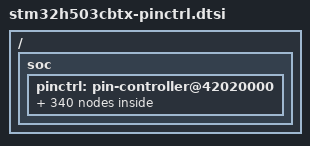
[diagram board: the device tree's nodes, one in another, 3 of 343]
/*
 * NOTE: Autogenerated file using genpinctrl.py
 *
 * SPDX-License-Identifier: Apache-2.0
 */

#include <zephyr/dt-bindings/pinctrl/stm32-pinctrl.h>

/ {
	soc {
		pinctrl: pin-controller@42020000 {

			/* ADC_IN / ADC_INN / ADC_INP */

			/omit-if-no-ref/ adc1_inn1_pa0: adc1_inn1_pa0 {
				pinmux = <STM32_PINMUX('A', 0, ANALOG)>;
			};

			/omit-if-no-ref/ adc1_inp0_pa0: adc1_inp0_pa0 {
				pinmux = <STM32_PINMUX('A', 0, ANALOG)>;
			};

			/omit-if-no-ref/ adc1_inp1_pa1: adc1_inp1_pa1 {
				pinmux = <STM32_PINMUX('A', 1, ANALOG)>;
			};

			/omit-if-no-ref/ adc1_inp14_pa2: adc1_inp14_pa2 {
				pinmux = <STM32_PINMUX('A', 2, ANALOG)>;
			};

			/omit-if-no-ref/ adc1_inp15_pa3: adc1_inp15_pa3 {
				pinmux = <STM32_PINMUX('A', 3, ANALOG)>;
			};

			/omit-if-no-ref/ adc1_inp18_pa4: adc1_inp18_pa4 {
				pinmux = <STM32_PINMUX('A', 4, ANALOG)>;
			};

			/omit-if-no-ref/ adc1_inn18_pa5: adc1_inn18_pa5 {
				pinmux = <STM32_PINMUX('A', 5, ANALOG)>;
			};

			/omit-if-no-ref/ adc1_inp19_pa5: adc1_inp19_pa5 {
				pinmux = <STM32_PINMUX('A', 5, ANALOG)>;
			};

			/omit-if-no-ref/ adc1_inp3_pa6: adc1_inp3_pa6 {
				pinmux = <STM32_PINMUX('A', 6, ANALOG)>;
			};

			/omit-if-no-ref/ adc1_inn3_pa7: adc1_inn3_pa7 {
				pinmux = <STM32_PINMUX('A', 7, ANALOG)>;
			};

			/omit-if-no-ref/ adc1_inp7_pa7: adc1_inp7_pa7 {
				pinmux = <STM32_PINMUX('A', 7, ANALOG)>;
			};

			/omit-if-no-ref/ adc1_inn5_pb0: adc1_inn5_pb0 {
				pinmux = <STM32_PINMUX('B', 0, ANALOG)>;
			};

			/omit-if-no-ref/ adc1_inp9_pb0: adc1_inp9_pb0 {
				pinmux = <STM32_PINMUX('B', 0, ANALOG)>;
			};

			/omit-if-no-ref/ adc1_inp5_pb1: adc1_inp5_pb1 {
				pinmux = <STM32_PINMUX('B', 1, ANALOG)>;
			};

			/* Analog */

			/omit-if-no-ref/ analog_pa0: analog_pa0 {
				pinmux = <STM32_PINMUX('A', 0, ANALOG)>;
			};

			/omit-if-no-ref/ analog_pa1: analog_pa1 {
				pinmux = <STM32_PINMUX('A', 1, ANALOG)>;
			};

			/omit-if-no-ref/ analog_pa2: analog_pa2 {
				pinmux = <STM32_PINMUX('A', 2, ANALOG)>;
			};

			/omit-if-no-ref/ analog_pa3: analog_pa3 {
				pinmux = <STM32_PINMUX('A', 3, ANALOG)>;
			};

			/omit-if-no-ref/ analog_pa4: analog_pa4 {
				pinmux = <STM32_PINMUX('A', 4, ANALOG)>;
			};

			/omit-if-no-ref/ analog_pa5: analog_pa5 {
				pinmux = <STM32_PINMUX('A', 5, ANALOG)>;
			};

			/omit-if-no-ref/ analog_pa6: analog_pa6 {
				pinmux = <STM32_PINMUX('A', 6, ANALOG)>;
			};

			/omit-if-no-ref/ analog_pa7: analog_pa7 {
				pinmux = <STM32_PINMUX('A', 7, ANALOG)>;
			};

			/omit-if-no-ref/ analog_pa8: analog_pa8 {
				pinmux = <STM32_PINMUX('A', 8, ANALOG)>;
			};

			/omit-if-no-ref/ analog_pa9: analog_pa9 {
				pinmux = <STM32_PINMUX('A', 9, ANALOG)>;
			};

			/omit-if-no-ref/ analog_pa10: analog_pa10 {
				pinmux = <STM32_PINMUX('A', 10, ANALOG)>;
			};

			/omit-if-no-ref/ analog_pa11: analog_pa11 {
				pinmux = <STM32_PINMUX('A', 11, ANALOG)>;
			};

			/omit-if-no-ref/ analog_pa12: analog_pa12 {
				pinmux = <STM32_PINMUX('A', 12, ANALOG)>;
			};

			/omit-if-no-ref/ analog_pa13: analog_pa13 {
				pinmux = <STM32_PINMUX('A', 13, ANALOG)>;
			};

			/omit-if-no-ref/ analog_pa14: analog_pa14 {
				pinmux = <STM32_PINMUX('A', 14, ANALOG)>;
			};

			/omit-if-no-ref/ analog_pa15: analog_pa15 {
				pinmux = <STM32_PINMUX('A', 15, ANALOG)>;
			};

			/omit-if-no-ref/ analog_pb0: analog_pb0 {
				pinmux = <STM32_PINMUX('B', 0, ANALOG)>;
			};

			/omit-if-no-ref/ analog_pb1: analog_pb1 {
				pinmux = <STM32_PINMUX('B', 1, ANALOG)>;
			};

			/omit-if-no-ref/ analog_pb2: analog_pb2 {
				pinmux = <STM32_PINMUX('B', 2, ANALOG)>;
			};

			/omit-if-no-ref/ analog_pb3: analog_pb3 {
				pinmux = <STM32_PINMUX('B', 3, ANALOG)>;
			};

			/omit-if-no-ref/ analog_pb4: analog_pb4 {
				pinmux = <STM32_PINMUX('B', 4, ANALOG)>;
			};

			/omit-if-no-ref/ analog_pb5: analog_pb5 {
				pinmux = <STM32_PINMUX('B', 5, ANALOG)>;
			};

			/omit-if-no-ref/ analog_pb6: analog_pb6 {
				pinmux = <STM32_PINMUX('B', 6, ANALOG)>;
			};

			/omit-if-no-ref/ analog_pb7: analog_pb7 {
				pinmux = <STM32_PINMUX('B', 7, ANALOG)>;
			};

			/omit-if-no-ref/ analog_pb8: analog_pb8 {
				pinmux = <STM32_PINMUX('B', 8, ANALOG)>;
			};

			/omit-if-no-ref/ analog_pb10: analog_pb10 {
				pinmux = <STM32_PINMUX('B', 10, ANALOG)>;
			};

			/omit-if-no-ref/ analog_pb12: analog_pb12 {
				pinmux = <STM32_PINMUX('B', 12, ANALOG)>;
			};

			/omit-if-no-ref/ analog_pb13: analog_pb13 {
				pinmux = <STM32_PINMUX('B', 13, ANALOG)>;
			};

			/omit-if-no-ref/ analog_pb14: analog_pb14 {
				pinmux = <STM32_PINMUX('B', 14, ANALOG)>;
			};

			/omit-if-no-ref/ analog_pb15: analog_pb15 {
				pinmux = <STM32_PINMUX('B', 15, ANALOG)>;
			};

			/omit-if-no-ref/ analog_pc13: analog_pc13 {
				pinmux = <STM32_PINMUX('C', 13, ANALOG)>;
			};

			/omit-if-no-ref/ analog_pc14: analog_pc14 {
				pinmux = <STM32_PINMUX('C', 14, ANALOG)>;
			};

			/omit-if-no-ref/ analog_pc15: analog_pc15 {
				pinmux = <STM32_PINMUX('C', 15, ANALOG)>;
			};

			/omit-if-no-ref/ analog_ph0: analog_ph0 {
				pinmux = <STM32_PINMUX('H', 0, ANALOG)>;
			};

			/omit-if-no-ref/ analog_ph1: analog_ph1 {
				pinmux = <STM32_PINMUX('H', 1, ANALOG)>;
			};

			/* COMP_IN */

			/omit-if-no-ref/ comp1_inp_pa0: comp1_inp_pa0 {
				pinmux = <STM32_PINMUX('A', 0, ANALOG)>;
			};

			/omit-if-no-ref/ comp1_inm_pa5: comp1_inm_pa5 {
				pinmux = <STM32_PINMUX('A', 5, ANALOG)>;
			};

			/omit-if-no-ref/ comp1_inp_pb0: comp1_inp_pb0 {
				pinmux = <STM32_PINMUX('B', 0, ANALOG)>;
			};

			/omit-if-no-ref/ comp1_inm_pb1: comp1_inm_pb1 {
				pinmux = <STM32_PINMUX('B', 1, ANALOG)>;
			};

			/omit-if-no-ref/ comp1_inp_pb2: comp1_inp_pb2 {
				pinmux = <STM32_PINMUX('B', 2, ANALOG)>;
			};

			/* COMP_OUT */

			/omit-if-no-ref/ comp1_out_pa13: comp1_out_pa13 {
				pinmux = <STM32_PINMUX('A', 13, AF12)>;
			};

			/omit-if-no-ref/ comp1_out_pb1: comp1_out_pb1 {
				pinmux = <STM32_PINMUX('B', 1, AF12)>;
			};

			/omit-if-no-ref/ comp1_out_pb15: comp1_out_pb15 {
				pinmux = <STM32_PINMUX('B', 15, AF12)>;
			};

			/* DAC_OUT */

			/omit-if-no-ref/ dac1_out1_pa4: dac1_out1_pa4 {
				pinmux = <STM32_PINMUX('A', 4, ANALOG)>;
			};

			/omit-if-no-ref/ dac1_out2_pa5: dac1_out2_pa5 {
				pinmux = <STM32_PINMUX('A', 5, ANALOG)>;
			};

			/* FDCAN_RX */

			/omit-if-no-ref/ fdcan1_rx_pa8: fdcan1_rx_pa8 {
				pinmux = <STM32_PINMUX('A', 8, AF9)>;
			};

			/omit-if-no-ref/ fdcan1_rx_pa11: fdcan1_rx_pa11 {
				pinmux = <STM32_PINMUX('A', 11, AF9)>;
			};

			/omit-if-no-ref/ fdcan1_rx_pb3: fdcan1_rx_pb3 {
				pinmux = <STM32_PINMUX('B', 3, AF9)>;
			};

			/omit-if-no-ref/ fdcan1_rx_pb5: fdcan1_rx_pb5 {
				pinmux = <STM32_PINMUX('B', 5, AF9)>;
			};

			/omit-if-no-ref/ fdcan1_rx_pb8: fdcan1_rx_pb8 {
				pinmux = <STM32_PINMUX('B', 8, AF9)>;
			};

			/omit-if-no-ref/ fdcan1_rx_pb12: fdcan1_rx_pb12 {
				pinmux = <STM32_PINMUX('B', 12, AF9)>;
			};

			/* FDCAN_TX */

			/omit-if-no-ref/ fdcan1_tx_pa12: fdcan1_tx_pa12 {
				pinmux = <STM32_PINMUX('A', 12, AF9)>;
			};

			/omit-if-no-ref/ fdcan1_tx_pb4: fdcan1_tx_pb4 {
				pinmux = <STM32_PINMUX('B', 4, AF9)>;
			};

			/omit-if-no-ref/ fdcan1_tx_pb6: fdcan1_tx_pb6 {
				pinmux = <STM32_PINMUX('B', 6, AF9)>;
			};

			/omit-if-no-ref/ fdcan1_tx_pb7: fdcan1_tx_pb7 {
				pinmux = <STM32_PINMUX('B', 7, AF9)>;
			};

			/omit-if-no-ref/ fdcan1_tx_pb10: fdcan1_tx_pb10 {
				pinmux = <STM32_PINMUX('B', 10, AF9)>;
			};

			/omit-if-no-ref/ fdcan1_tx_pb13: fdcan1_tx_pb13 {
				pinmux = <STM32_PINMUX('B', 13, AF9)>;
			};

			/omit-if-no-ref/ fdcan1_tx_pb15: fdcan1_tx_pb15 {
				pinmux = <STM32_PINMUX('B', 15, AF9)>;
			};

			/* I2C_SCL */

			/omit-if-no-ref/ i2c1_scl_pb6: i2c1_scl_pb6 {
				pinmux = <STM32_PINMUX('B', 6, AF4)>;
				bias-pull-up;
				drive-open-drain;
			};

			/omit-if-no-ref/ i2c1_scl_pb8: i2c1_scl_pb8 {
				pinmux = <STM32_PINMUX('B', 8, AF4)>;
				bias-pull-up;
				drive-open-drain;
			};

			/omit-if-no-ref/ i2c2_scl_pb3: i2c2_scl_pb3 {
				pinmux = <STM32_PINMUX('B', 3, AF8)>;
				bias-pull-up;
				drive-open-drain;
			};

			/omit-if-no-ref/ i2c2_scl_pb5: i2c2_scl_pb5 {
				pinmux = <STM32_PINMUX('B', 5, AF8)>;
				bias-pull-up;
				drive-open-drain;
			};

			/omit-if-no-ref/ i2c2_scl_pb10: i2c2_scl_pb10 {
				pinmux = <STM32_PINMUX('B', 10, AF4)>;
				bias-pull-up;
				drive-open-drain;
			};

			/* I2C_SDA */

			/omit-if-no-ref/ i2c1_sda_pb5: i2c1_sda_pb5 {
				pinmux = <STM32_PINMUX('B', 5, AF11)>;
				bias-pull-up;
				drive-open-drain;
			};

			/omit-if-no-ref/ i2c1_sda_pb7: i2c1_sda_pb7 {
				pinmux = <STM32_PINMUX('B', 7, AF4)>;
				bias-pull-up;
				drive-open-drain;
			};

			/omit-if-no-ref/ i2c1_sda_pb10: i2c1_sda_pb10 {
				pinmux = <STM32_PINMUX('B', 10, AF11)>;
				bias-pull-up;
				drive-open-drain;
			};

			/omit-if-no-ref/ i2c2_sda_pb3: i2c2_sda_pb3 {
				pinmux = <STM32_PINMUX('B', 3, AF4)>;
				bias-pull-up;
				drive-open-drain;
			};

			/omit-if-no-ref/ i2c2_sda_pb4: i2c2_sda_pb4 {
				pinmux = <STM32_PINMUX('B', 4, AF8)>;
				bias-pull-up;
				drive-open-drain;
			};

			/omit-if-no-ref/ i2c2_sda_pb8: i2c2_sda_pb8 {
				pinmux = <STM32_PINMUX('B', 8, AF8)>;
				bias-pull-up;
				drive-open-drain;
			};

			/omit-if-no-ref/ i2c2_sda_pb13: i2c2_sda_pb13 {
				pinmux = <STM32_PINMUX('B', 13, AF4)>;
				bias-pull-up;
				drive-open-drain;
			};

			/* I2C_SMBA */

			/omit-if-no-ref/ i2c1_smba_pb3: i2c1_smba_pb3 {
				pinmux = <STM32_PINMUX('B', 3, AF11)>;
				bias-pull-up;
			};

			/omit-if-no-ref/ i2c1_smba_pb4: i2c1_smba_pb4 {
				pinmux = <STM32_PINMUX('B', 4, AF11)>;
				bias-pull-up;
			};

			/omit-if-no-ref/ i2c1_smba_pb5: i2c1_smba_pb5 {
				pinmux = <STM32_PINMUX('B', 5, AF4)>;
				bias-pull-up;
			};

			/omit-if-no-ref/ i2c1_smba_pb13: i2c1_smba_pb13 {
				pinmux = <STM32_PINMUX('B', 13, AF11)>;
				bias-pull-up;
			};

			/omit-if-no-ref/ i2c2_smba_pb7: i2c2_smba_pb7 {
				pinmux = <STM32_PINMUX('B', 7, AF11)>;
				bias-pull-up;
			};

			/omit-if-no-ref/ i2c2_smba_pb8: i2c2_smba_pb8 {
				pinmux = <STM32_PINMUX('B', 8, AF11)>;
				bias-pull-up;
			};

			/omit-if-no-ref/ i2c2_smba_pb12: i2c2_smba_pb12 {
				pinmux = <STM32_PINMUX('B', 12, AF4)>;
				bias-pull-up;
			};

			/* I2S_CK */

			/omit-if-no-ref/ i2s1_ck_pa2: i2s1_ck_pa2 {
				pinmux = <STM32_PINMUX('A', 2, AF4)>;
				slew-rate = "very-high-speed";
			};

			/omit-if-no-ref/ i2s1_ck_pa5: i2s1_ck_pa5 {
				pinmux = <STM32_PINMUX('A', 5, AF5)>;
				slew-rate = "very-high-speed";
			};

			/omit-if-no-ref/ i2s1_ck_pa8: i2s1_ck_pa8 {
				pinmux = <STM32_PINMUX('A', 8, AF12)>;
				slew-rate = "very-high-speed";
			};

			/omit-if-no-ref/ i2s1_ck_pb3: i2s1_ck_pb3 {
				pinmux = <STM32_PINMUX('B', 3, AF5)>;
				slew-rate = "very-high-speed";
			};

			/omit-if-no-ref/ i2s2_ck_pa5: i2s2_ck_pa5 {
				pinmux = <STM32_PINMUX('A', 5, AF7)>;
				slew-rate = "very-high-speed";
			};

			/omit-if-no-ref/ i2s2_ck_pa9: i2s2_ck_pa9 {
				pinmux = <STM32_PINMUX('A', 9, AF5)>;
				slew-rate = "very-high-speed";
			};

			/omit-if-no-ref/ i2s2_ck_pa12: i2s2_ck_pa12 {
				pinmux = <STM32_PINMUX('A', 12, AF5)>;
				slew-rate = "very-high-speed";
			};

			/omit-if-no-ref/ i2s2_ck_pb2: i2s2_ck_pb2 {
				pinmux = <STM32_PINMUX('B', 2, AF6)>;
				slew-rate = "very-high-speed";
			};

			/omit-if-no-ref/ i2s2_ck_pb10: i2s2_ck_pb10 {
				pinmux = <STM32_PINMUX('B', 10, AF5)>;
				slew-rate = "very-high-speed";
			};

			/omit-if-no-ref/ i2s2_ck_pb13: i2s2_ck_pb13 {
				pinmux = <STM32_PINMUX('B', 13, AF5)>;
				slew-rate = "very-high-speed";
			};

			/omit-if-no-ref/ i2s3_ck_pa1: i2s3_ck_pa1 {
				pinmux = <STM32_PINMUX('A', 1, AF6)>;
				slew-rate = "very-high-speed";
			};

			/omit-if-no-ref/ i2s3_ck_pa15: i2s3_ck_pa15 {
				pinmux = <STM32_PINMUX('A', 15, AF10)>;
				slew-rate = "very-high-speed";
			};

			/omit-if-no-ref/ i2s3_ck_pb3: i2s3_ck_pb3 {
				pinmux = <STM32_PINMUX('B', 3, AF6)>;
				slew-rate = "very-high-speed";
			};

			/omit-if-no-ref/ i2s3_ck_pb7: i2s3_ck_pb7 {
				pinmux = <STM32_PINMUX('B', 7, AF6)>;
				slew-rate = "very-high-speed";
			};

			/* I2S_MCK */

			/omit-if-no-ref/ i2s1_mck_pa5: i2s1_mck_pa5 {
				pinmux = <STM32_PINMUX('A', 5, AF6)>;
				slew-rate = "very-high-speed";
			};

			/omit-if-no-ref/ i2s1_mck_pa7: i2s1_mck_pa7 {
				pinmux = <STM32_PINMUX('A', 7, AF4)>;
				slew-rate = "very-high-speed";
			};

			/omit-if-no-ref/ i2s1_mck_pb6: i2s1_mck_pb6 {
				pinmux = <STM32_PINMUX('B', 6, AF5)>;
				slew-rate = "very-high-speed";
			};

			/omit-if-no-ref/ i2s2_mck_pa0: i2s2_mck_pa0 {
				pinmux = <STM32_PINMUX('A', 0, AF11)>;
				slew-rate = "very-high-speed";
			};

			/omit-if-no-ref/ i2s2_mck_pa7: i2s2_mck_pa7 {
				pinmux = <STM32_PINMUX('A', 7, AF6)>;
				slew-rate = "very-high-speed";
			};

			/omit-if-no-ref/ i2s2_mck_pb3: i2s2_mck_pb3 {
				pinmux = <STM32_PINMUX('B', 3, AF7)>;
				slew-rate = "very-high-speed";
			};

			/omit-if-no-ref/ i2s2_mck_pb8: i2s2_mck_pb8 {
				pinmux = <STM32_PINMUX('B', 8, AF6)>;
				slew-rate = "very-high-speed";
			};

			/omit-if-no-ref/ i2s3_mck_pa7: i2s3_mck_pa7 {
				pinmux = <STM32_PINMUX('A', 7, AF10)>;
				slew-rate = "very-high-speed";
			};

			/omit-if-no-ref/ i2s3_mck_pb7: i2s3_mck_pb7 {
				pinmux = <STM32_PINMUX('B', 7, AF10)>;
				slew-rate = "very-high-speed";
			};

			/omit-if-no-ref/ i2s3_mck_pb15: i2s3_mck_pb15 {
				pinmux = <STM32_PINMUX('B', 15, AF10)>;
				slew-rate = "very-high-speed";
			};

			/* I2S_WS */

			/omit-if-no-ref/ i2s1_ws_pa1: i2s1_ws_pa1 {
				pinmux = <STM32_PINMUX('A', 1, AF4)>;
			};

			/omit-if-no-ref/ i2s1_ws_pa4: i2s1_ws_pa4 {
				pinmux = <STM32_PINMUX('A', 4, AF5)>;
			};

			/omit-if-no-ref/ i2s1_ws_pa15: i2s1_ws_pa15 {
				pinmux = <STM32_PINMUX('A', 15, AF5)>;
			};

			/omit-if-no-ref/ i2s1_ws_pb8: i2s1_ws_pb8 {
				pinmux = <STM32_PINMUX('B', 8, AF12)>;
			};

			/omit-if-no-ref/ i2s2_ws_pa3: i2s2_ws_pa3 {
				pinmux = <STM32_PINMUX('A', 3, AF5)>;
			};

			/omit-if-no-ref/ i2s2_ws_pa8: i2s2_ws_pa8 {
				pinmux = <STM32_PINMUX('A', 8, AF11)>;
			};

			/omit-if-no-ref/ i2s2_ws_pa11: i2s2_ws_pa11 {
				pinmux = <STM32_PINMUX('A', 11, AF5)>;
			};

			/omit-if-no-ref/ i2s2_ws_pb4: i2s2_ws_pb4 {
				pinmux = <STM32_PINMUX('B', 4, AF7)>;
			};

			/omit-if-no-ref/ i2s2_ws_pb12: i2s2_ws_pb12 {
				pinmux = <STM32_PINMUX('B', 12, AF5)>;
			};

			/omit-if-no-ref/ i2s3_ws_pa0: i2s3_ws_pa0 {
				pinmux = <STM32_PINMUX('A', 0, AF10)>;
			};

			/omit-if-no-ref/ i2s3_ws_pa4: i2s3_ws_pa4 {
				pinmux = <STM32_PINMUX('A', 4, AF6)>;
			};

			/omit-if-no-ref/ i2s3_ws_pa15: i2s3_ws_pa15 {
				pinmux = <STM32_PINMUX('A', 15, AF6)>;
			};

			/omit-if-no-ref/ i2s3_ws_pb10: i2s3_ws_pb10 {
				pinmux = <STM32_PINMUX('B', 10, AF6)>;
			};

			/* I3C_SCL */

			/omit-if-no-ref/ i3c1_scl_pb6: i3c1_scl_pb6 {
				pinmux = <STM32_PINMUX('B', 6, AF3)>;
				slew-rate = "very-high-speed";
			};

			/omit-if-no-ref/ i3c1_scl_pb8: i3c1_scl_pb8 {
				pinmux = <STM32_PINMUX('B', 8, AF3)>;
				slew-rate = "very-high-speed";
			};

			/omit-if-no-ref/ i3c2_scl_pb3: i3c2_scl_pb3 {
				pinmux = <STM32_PINMUX('B', 3, AF3)>;
				slew-rate = "very-high-speed";
			};

			/omit-if-no-ref/ i3c2_scl_pb5: i3c2_scl_pb5 {
				pinmux = <STM32_PINMUX('B', 5, AF3)>;
				slew-rate = "very-high-speed";
			};

			/omit-if-no-ref/ i3c2_scl_pb10: i3c2_scl_pb10 {
				pinmux = <STM32_PINMUX('B', 10, AF10)>;
				slew-rate = "very-high-speed";
			};

			/* I3C_SDA */

			/omit-if-no-ref/ i3c1_sda_pb5: i3c1_sda_pb5 {
				pinmux = <STM32_PINMUX('B', 5, AF10)>;
				slew-rate = "very-high-speed";
			};

			/omit-if-no-ref/ i3c1_sda_pb7: i3c1_sda_pb7 {
				pinmux = <STM32_PINMUX('B', 7, AF3)>;
				slew-rate = "very-high-speed";
			};

			/omit-if-no-ref/ i3c1_sda_pb10: i3c1_sda_pb10 {
				pinmux = <STM32_PINMUX('B', 10, AF8)>;
				slew-rate = "very-high-speed";
			};

			/omit-if-no-ref/ i3c2_sda_pb4: i3c2_sda_pb4 {
				pinmux = <STM32_PINMUX('B', 4, AF3)>;
				slew-rate = "very-high-speed";
			};

			/omit-if-no-ref/ i3c2_sda_pb8: i3c2_sda_pb8 {
				pinmux = <STM32_PINMUX('B', 8, AF10)>;
				slew-rate = "very-high-speed";
			};

			/omit-if-no-ref/ i3c2_sda_pb13: i3c2_sda_pb13 {
				pinmux = <STM32_PINMUX('B', 13, AF10)>;
				slew-rate = "very-high-speed";
			};

			/* JTAG PORT */

			/omit-if-no-ref/ debug_jtms_swdio_pa13: debug_jtms_swdio_pa13 {
				pinmux = <STM32_PINMUX('A', 13, AF0)>;
			};

			/omit-if-no-ref/ debug_jtck_swclk_pa14: debug_jtck_swclk_pa14 {
				pinmux = <STM32_PINMUX('A', 14, AF0)>;
			};

			/omit-if-no-ref/ debug_jtdi_pa15: debug_jtdi_pa15 {
				pinmux = <STM32_PINMUX('A', 15, AF0)>;
			};

			/omit-if-no-ref/ debug_jtdo_swo_pb3: debug_jtdo_swo_pb3 {
				pinmux = <STM32_PINMUX('B', 3, AF0)>;
			};

			/omit-if-no-ref/ debug_jtrst_pb4: debug_jtrst_pb4 {
				pinmux = <STM32_PINMUX('B', 4, AF0)>;
			};

			/* OPAMP */

			/omit-if-no-ref/ opamp1_vinp_pa0: opamp1_vinp_pa0 {
				pinmux = <STM32_PINMUX('A', 0, ANALOG)>;
			};

			/omit-if-no-ref/ opamp1_vout_pa7: opamp1_vout_pa7 {
				pinmux = <STM32_PINMUX('A', 7, ANALOG)>;
			};

			/omit-if-no-ref/ opamp1_vinp_pb0: opamp1_vinp_pb0 {
				pinmux = <STM32_PINMUX('B', 0, ANALOG)>;
			};

			/omit-if-no-ref/ opamp1_vinm_pb1: opamp1_vinm_pb1 {
				pinmux = <STM32_PINMUX('B', 1, ANALOG)>;
			};

			/* RCC_MCO */

			/omit-if-no-ref/ rcc_mco_1_pa8: rcc_mco_1_pa8 {
				pinmux = <STM32_PINMUX('A', 8, AF0)>;
				slew-rate = "very-high-speed";
			};

			/* SPI_MISO */

			/omit-if-no-ref/ spi1_miso_pa0: spi1_miso_pa0 {
				pinmux = <STM32_PINMUX('A', 0, AF12)>;
				bias-pull-down;
			};

			/omit-if-no-ref/ spi1_miso_pa3: spi1_miso_pa3 {
				pinmux = <STM32_PINMUX('A', 3, AF4)>;
				bias-pull-down;
			};

			/omit-if-no-ref/ spi1_miso_pa6: spi1_miso_pa6 {
				pinmux = <STM32_PINMUX('A', 6, AF5)>;
				bias-pull-down;
			};

			/omit-if-no-ref/ spi1_miso_pa9: spi1_miso_pa9 {
				pinmux = <STM32_PINMUX('A', 9, AF4)>;
				bias-pull-down;
			};

			/omit-if-no-ref/ spi1_miso_pb4: spi1_miso_pb4 {
				pinmux = <STM32_PINMUX('B', 4, AF5)>;
				bias-pull-down;
			};

			/omit-if-no-ref/ spi2_miso_pa7: spi2_miso_pa7 {
				pinmux = <STM32_PINMUX('A', 7, AF11)>;
				bias-pull-down;
			};

			/omit-if-no-ref/ spi2_miso_pa15: spi2_miso_pa15 {
				pinmux = <STM32_PINMUX('A', 15, AF7)>;
				bias-pull-down;
			};

			/omit-if-no-ref/ spi2_miso_pb5: spi2_miso_pb5 {
				pinmux = <STM32_PINMUX('B', 5, AF6)>;
				bias-pull-down;
			};

			/omit-if-no-ref/ spi2_miso_pb14: spi2_miso_pb14 {
				pinmux = <STM32_PINMUX('B', 14, AF5)>;
				bias-pull-down;
			};

			/omit-if-no-ref/ spi3_miso_pa2: spi3_miso_pa2 {
				pinmux = <STM32_PINMUX('A', 2, AF6)>;
				bias-pull-down;
			};

			/omit-if-no-ref/ spi3_miso_pa4: spi3_miso_pa4 {
				pinmux = <STM32_PINMUX('A', 4, AF10)>;
				bias-pull-down;
			};

			/omit-if-no-ref/ spi3_miso_pb4: spi3_miso_pb4 {
				pinmux = <STM32_PINMUX('B', 4, AF6)>;
				bias-pull-down;
			};

			/omit-if-no-ref/ spi3_miso_pb15: spi3_miso_pb15 {
				pinmux = <STM32_PINMUX('B', 15, AF6)>;
				bias-pull-down;
			};

			/* SPI_MOSI */

			/omit-if-no-ref/ spi1_mosi_pa4: spi1_mosi_pa4 {
				pinmux = <STM32_PINMUX('A', 4, AF4)>;
				bias-pull-down;
			};

			/omit-if-no-ref/ spi1_mosi_pa7: spi1_mosi_pa7 {
				pinmux = <STM32_PINMUX('A', 7, AF5)>;
				bias-pull-down;
			};

			/omit-if-no-ref/ spi1_mosi_pb5: spi1_mosi_pb5 {
				pinmux = <STM32_PINMUX('B', 5, AF5)>;
				bias-pull-down;
			};

			/omit-if-no-ref/ spi2_mosi_pa8: spi2_mosi_pa8 {
				pinmux = <STM32_PINMUX('A', 8, AF6)>;
				bias-pull-down;
			};

			/omit-if-no-ref/ spi2_mosi_pb1: spi2_mosi_pb1 {
				pinmux = <STM32_PINMUX('B', 1, AF6)>;
				bias-pull-down;
			};

			/omit-if-no-ref/ spi2_mosi_pb15: spi2_mosi_pb15 {
				pinmux = <STM32_PINMUX('B', 15, AF5)>;
				bias-pull-down;
			};

			/omit-if-no-ref/ spi3_mosi_pa3: spi3_mosi_pa3 {
				pinmux = <STM32_PINMUX('A', 3, AF6)>;
				bias-pull-down;
			};

			/omit-if-no-ref/ spi3_mosi_pa5: spi3_mosi_pa5 {
				pinmux = <STM32_PINMUX('A', 5, AF10)>;
				bias-pull-down;
			};

			/omit-if-no-ref/ spi3_mosi_pa9: spi3_mosi_pa9 {
				pinmux = <STM32_PINMUX('A', 9, AF10)>;
				bias-pull-down;
			};

			/omit-if-no-ref/ spi3_mosi_pb2: spi3_mosi_pb2 {
				pinmux = <STM32_PINMUX('B', 2, AF7)>;
				bias-pull-down;
			};

			/omit-if-no-ref/ spi3_mosi_pb5: spi3_mosi_pb5 {
				pinmux = <STM32_PINMUX('B', 5, AF7)>;
				bias-pull-down;
			};

			/* SPI_NSS */

			/omit-if-no-ref/ spi1_nss_pa1: spi1_nss_pa1 {
				pinmux = <STM32_PINMUX('A', 1, AF4)>;
				bias-pull-up;
			};

			/omit-if-no-ref/ spi1_nss_pa4: spi1_nss_pa4 {
				pinmux = <STM32_PINMUX('A', 4, AF5)>;
				bias-pull-up;
			};

			/omit-if-no-ref/ spi1_nss_pa15: spi1_nss_pa15 {
				pinmux = <STM32_PINMUX('A', 15, AF5)>;
				bias-pull-up;
			};

			/omit-if-no-ref/ spi1_nss_pb8: spi1_nss_pb8 {
				pinmux = <STM32_PINMUX('B', 8, AF12)>;
				bias-pull-up;
			};

			/omit-if-no-ref/ spi2_nss_pa3: spi2_nss_pa3 {
				pinmux = <STM32_PINMUX('A', 3, AF5)>;
				bias-pull-up;
			};

			/omit-if-no-ref/ spi2_nss_pa8: spi2_nss_pa8 {
				pinmux = <STM32_PINMUX('A', 8, AF11)>;
				bias-pull-up;
			};

			/omit-if-no-ref/ spi2_nss_pa11: spi2_nss_pa11 {
				pinmux = <STM32_PINMUX('A', 11, AF5)>;
				bias-pull-up;
			};

			/omit-if-no-ref/ spi2_nss_pb4: spi2_nss_pb4 {
				pinmux = <STM32_PINMUX('B', 4, AF7)>;
				bias-pull-up;
			};

			/omit-if-no-ref/ spi2_nss_pb12: spi2_nss_pb12 {
				pinmux = <STM32_PINMUX('B', 12, AF5)>;
				bias-pull-up;
			};

			/omit-if-no-ref/ spi3_nss_pa0: spi3_nss_pa0 {
				pinmux = <STM32_PINMUX('A', 0, AF10)>;
				bias-pull-up;
			};

			/omit-if-no-ref/ spi3_nss_pa4: spi3_nss_pa4 {
				pinmux = <STM32_PINMUX('A', 4, AF6)>;
				bias-pull-up;
			};

			/omit-if-no-ref/ spi3_nss_pa15: spi3_nss_pa15 {
				pinmux = <STM32_PINMUX('A', 15, AF6)>;
				bias-pull-up;
			};

			/omit-if-no-ref/ spi3_nss_pb10: spi3_nss_pb10 {
				pinmux = <STM32_PINMUX('B', 10, AF6)>;
				bias-pull-up;
			};

			/* SPI_SCK */

			/omit-if-no-ref/ spi1_sck_pa2: spi1_sck_pa2 {
				pinmux = <STM32_PINMUX('A', 2, AF4)>;
				bias-pull-down;
				slew-rate = "very-high-speed";
			};

			/omit-if-no-ref/ spi1_sck_pa5: spi1_sck_pa5 {
				pinmux = <STM32_PINMUX('A', 5, AF5)>;
				bias-pull-down;
				slew-rate = "very-high-speed";
			};

			/omit-if-no-ref/ spi1_sck_pa8: spi1_sck_pa8 {
				pinmux = <STM32_PINMUX('A', 8, AF12)>;
				bias-pull-down;
				slew-rate = "very-high-speed";
			};

			/omit-if-no-ref/ spi1_sck_pb3: spi1_sck_pb3 {
				pinmux = <STM32_PINMUX('B', 3, AF5)>;
				bias-pull-down;
				slew-rate = "very-high-speed";
			};

			/omit-if-no-ref/ spi2_sck_pa5: spi2_sck_pa5 {
				pinmux = <STM32_PINMUX('A', 5, AF7)>;
				bias-pull-down;
				slew-rate = "very-high-speed";
			};

			/omit-if-no-ref/ spi2_sck_pa9: spi2_sck_pa9 {
				pinmux = <STM32_PINMUX('A', 9, AF5)>;
				bias-pull-down;
				slew-rate = "very-high-speed";
			};

			/omit-if-no-ref/ spi2_sck_pa12: spi2_sck_pa12 {
				pinmux = <STM32_PINMUX('A', 12, AF5)>;
				bias-pull-down;
				slew-rate = "very-high-speed";
			};

			/omit-if-no-ref/ spi2_sck_pb2: spi2_sck_pb2 {
				pinmux = <STM32_PINMUX('B', 2, AF6)>;
				bias-pull-down;
				slew-rate = "very-high-speed";
			};

			/omit-if-no-ref/ spi2_sck_pb10: spi2_sck_pb10 {
				pinmux = <STM32_PINMUX('B', 10, AF5)>;
				bias-pull-down;
				slew-rate = "very-high-speed";
			};

			/omit-if-no-ref/ spi2_sck_pb13: spi2_sck_pb13 {
				pinmux = <STM32_PINMUX('B', 13, AF5)>;
				bias-pull-down;
				slew-rate = "very-high-speed";
			};

			/omit-if-no-ref/ spi3_sck_pa1: spi3_sck_pa1 {
				pinmux = <STM32_PINMUX('A', 1, AF6)>;
				bias-pull-down;
				slew-rate = "very-high-speed";
			};

			/omit-if-no-ref/ spi3_sck_pa15: spi3_sck_pa15 {
				pinmux = <STM32_PINMUX('A', 15, AF10)>;
				bias-pull-down;
				slew-rate = "very-high-speed";
			};

			/omit-if-no-ref/ spi3_sck_pb3: spi3_sck_pb3 {
				pinmux = <STM32_PINMUX('B', 3, AF6)>;
				bias-pull-down;
				slew-rate = "very-high-speed";
			};

			/omit-if-no-ref/ spi3_sck_pb7: spi3_sck_pb7 {
				pinmux = <STM32_PINMUX('B', 7, AF6)>;
				bias-pull-down;
				slew-rate = "very-high-speed";
			};

			/* TIM_BKIN */

			/omit-if-no-ref/ tim1_bkin_pa4: tim1_bkin_pa4 {
				pinmux = <STM32_PINMUX('A', 4, AF14)>;
			};

			/omit-if-no-ref/ tim1_bkin_pa6: tim1_bkin_pa6 {
				pinmux = <STM32_PINMUX('A', 6, AF1)>;
			};

			/omit-if-no-ref/ tim1_bkin_pb3: tim1_bkin_pb3 {
				pinmux = <STM32_PINMUX('B', 3, AF14)>;
			};

			/omit-if-no-ref/ tim1_bkin2_pb8: tim1_bkin2_pb8 {
				pinmux = <STM32_PINMUX('B', 8, AF1)>;
			};

			/omit-if-no-ref/ tim1_bkin_pb12: tim1_bkin_pb12 {
				pinmux = <STM32_PINMUX('B', 12, AF1)>;
			};

			/* TIM_CH / TIM_CHN */

			/omit-if-no-ref/ tim1_ch3_pa1: tim1_ch3_pa1 {
				pinmux = <STM32_PINMUX('A', 1, AF14)>;
			};

			/omit-if-no-ref/ tim1_ch4_pa2: tim1_ch4_pa2 {
				pinmux = <STM32_PINMUX('A', 2, AF14)>;
			};

			/omit-if-no-ref/ tim1_ch1n_pa3: tim1_ch1n_pa3 {
				pinmux = <STM32_PINMUX('A', 3, AF14)>;
			};

			/omit-if-no-ref/ tim1_ch2n_pa4: tim1_ch2n_pa4 {
				pinmux = <STM32_PINMUX('A', 4, AF1)>;
			};

			/omit-if-no-ref/ tim1_ch1n_pa7: tim1_ch1n_pa7 {
				pinmux = <STM32_PINMUX('A', 7, AF1)>;
			};

			/omit-if-no-ref/ tim1_ch1_pa8: tim1_ch1_pa8 {
				pinmux = <STM32_PINMUX('A', 8, AF1)>;
			};

			/omit-if-no-ref/ tim1_ch4n_pa8: tim1_ch4n_pa8 {
				pinmux = <STM32_PINMUX('A', 8, AF14)>;
			};

			/omit-if-no-ref/ tim1_ch2_pa9: tim1_ch2_pa9 {
				pinmux = <STM32_PINMUX('A', 9, AF1)>;
			};

			/omit-if-no-ref/ tim1_ch3_pa10: tim1_ch3_pa10 {
				pinmux = <STM32_PINMUX('A', 10, AF1)>;
			};

			/omit-if-no-ref/ tim1_ch4_pa11: tim1_ch4_pa11 {
				pinmux = <STM32_PINMUX('A', 11, AF1)>;
			};

			/omit-if-no-ref/ tim1_ch1_pa13: tim1_ch1_pa13 {
				pinmux = <STM32_PINMUX('A', 13, AF1)>;
			};

			/omit-if-no-ref/ tim1_ch2_pa14: tim1_ch2_pa14 {
				pinmux = <STM32_PINMUX('A', 14, AF1)>;
			};

			/omit-if-no-ref/ tim1_ch4n_pa14: tim1_ch4n_pa14 {
				pinmux = <STM32_PINMUX('A', 14, AF14)>;
			};

			/omit-if-no-ref/ tim1_ch2n_pb0: tim1_ch2n_pb0 {
				pinmux = <STM32_PINMUX('B', 0, AF1)>;
			};

			/omit-if-no-ref/ tim1_ch1_pb1: tim1_ch1_pb1 {
				pinmux = <STM32_PINMUX('B', 1, AF14)>;
			};

			/omit-if-no-ref/ tim1_ch3n_pb1: tim1_ch3n_pb1 {
				pinmux = <STM32_PINMUX('B', 1, AF1)>;
			};

			/omit-if-no-ref/ tim1_ch2n_pb2: tim1_ch2n_pb2 {
				pinmux = <STM32_PINMUX('B', 2, AF1)>;
			};

			/omit-if-no-ref/ tim1_ch2_pb4: tim1_ch2_pb4 {
				pinmux = <STM32_PINMUX('B', 4, AF14)>;
			};

			/omit-if-no-ref/ tim1_ch4n_pb4: tim1_ch4n_pb4 {
				pinmux = <STM32_PINMUX('B', 4, AF1)>;
			};

			/omit-if-no-ref/ tim1_ch3_pb5: tim1_ch3_pb5 {
				pinmux = <STM32_PINMUX('B', 5, AF1)>;
			};

			/omit-if-no-ref/ tim1_ch2_pb6: tim1_ch2_pb6 {
				pinmux = <STM32_PINMUX('B', 6, AF14)>;
			};

			/omit-if-no-ref/ tim1_ch3n_pb6: tim1_ch3n_pb6 {
				pinmux = <STM32_PINMUX('B', 6, AF1)>;
			};

			/omit-if-no-ref/ tim1_ch1_pb7: tim1_ch1_pb7 {
				pinmux = <STM32_PINMUX('B', 7, AF14)>;
			};

			/omit-if-no-ref/ tim1_ch2n_pb7: tim1_ch2n_pb7 {
				pinmux = <STM32_PINMUX('B', 7, AF1)>;
			};

			/omit-if-no-ref/ tim1_ch1n_pb13: tim1_ch1n_pb13 {
				pinmux = <STM32_PINMUX('B', 13, AF1)>;
			};

			/omit-if-no-ref/ tim1_ch2n_pb14: tim1_ch2n_pb14 {
				pinmux = <STM32_PINMUX('B', 14, AF1)>;
			};

			/omit-if-no-ref/ tim1_ch3n_pb15: tim1_ch3n_pb15 {
				pinmux = <STM32_PINMUX('B', 15, AF1)>;
			};

			/omit-if-no-ref/ tim2_ch1_pa0: tim2_ch1_pa0 {
				pinmux = <STM32_PINMUX('A', 0, AF1)>;
			};

			/omit-if-no-ref/ tim2_ch2_pa1: tim2_ch2_pa1 {
				pinmux = <STM32_PINMUX('A', 1, AF1)>;
			};

			/omit-if-no-ref/ tim2_ch3_pa2: tim2_ch3_pa2 {
				pinmux = <STM32_PINMUX('A', 2, AF1)>;
			};

			/omit-if-no-ref/ tim2_ch4_pa3: tim2_ch4_pa3 {
				pinmux = <STM32_PINMUX('A', 3, AF1)>;
			};

			/omit-if-no-ref/ tim2_ch1_pa5: tim2_ch1_pa5 {
				pinmux = <STM32_PINMUX('A', 5, AF1)>;
			};

			/omit-if-no-ref/ tim2_ch3_pa7: tim2_ch3_pa7 {
				pinmux = <STM32_PINMUX('A', 7, AF14)>;
			};

			/omit-if-no-ref/ tim2_ch4_pa12: tim2_ch4_pa12 {
				pinmux = <STM32_PINMUX('A', 12, AF14)>;
			};

			/omit-if-no-ref/ tim2_ch1_pa15: tim2_ch1_pa15 {
				pinmux = <STM32_PINMUX('A', 15, AF1)>;
			};

			/omit-if-no-ref/ tim2_ch1_pb2: tim2_ch1_pb2 {
				pinmux = <STM32_PINMUX('B', 2, AF14)>;
			};

			/omit-if-no-ref/ tim2_ch2_pb3: tim2_ch2_pb3 {
				pinmux = <STM32_PINMUX('B', 3, AF1)>;
			};

			/omit-if-no-ref/ tim2_ch3_pb10: tim2_ch3_pb10 {
				pinmux = <STM32_PINMUX('B', 10, AF1)>;
			};

			/omit-if-no-ref/ tim3_ch1_pa0: tim3_ch1_pa0 {
				pinmux = <STM32_PINMUX('A', 0, AF2)>;
			};

			/omit-if-no-ref/ tim3_ch1_pa6: tim3_ch1_pa6 {
				pinmux = <STM32_PINMUX('A', 6, AF2)>;
			};

			/omit-if-no-ref/ tim3_ch2_pa7: tim3_ch2_pa7 {
				pinmux = <STM32_PINMUX('A', 7, AF2)>;
			};

			/omit-if-no-ref/ tim3_ch3_pa8: tim3_ch3_pa8 {
				pinmux = <STM32_PINMUX('A', 8, AF2)>;
			};

			/omit-if-no-ref/ tim3_ch2_pa11: tim3_ch2_pa11 {
				pinmux = <STM32_PINMUX('A', 11, AF2)>;
			};

			/omit-if-no-ref/ tim3_ch4_pa12: tim3_ch4_pa12 {
				pinmux = <STM32_PINMUX('A', 12, AF2)>;
			};

			/omit-if-no-ref/ tim3_ch1_pa14: tim3_ch1_pa14 {
				pinmux = <STM32_PINMUX('A', 14, AF2)>;
			};

			/omit-if-no-ref/ tim3_ch3_pb0: tim3_ch3_pb0 {
				pinmux = <STM32_PINMUX('B', 0, AF2)>;
			};

			/omit-if-no-ref/ tim3_ch4_pb1: tim3_ch4_pb1 {
				pinmux = <STM32_PINMUX('B', 1, AF2)>;
			};

			/omit-if-no-ref/ tim3_ch1_pb4: tim3_ch1_pb4 {
				pinmux = <STM32_PINMUX('B', 4, AF2)>;
			};

			/omit-if-no-ref/ tim3_ch2_pb5: tim3_ch2_pb5 {
				pinmux = <STM32_PINMUX('B', 5, AF2)>;
			};

			/omit-if-no-ref/ tim3_ch3_pb6: tim3_ch3_pb6 {
				pinmux = <STM32_PINMUX('B', 6, AF2)>;
			};

			/omit-if-no-ref/ tim3_ch4_pb15: tim3_ch4_pb15 {
				pinmux = <STM32_PINMUX('B', 15, AF14)>;
			};

			/* UART_CTS / USART_CTS / LPUART_CTS */

			/omit-if-no-ref/ usart1_cts_pa0: usart1_cts_pa0 {
				pinmux = <STM32_PINMUX('A', 0, AF8)>;
				bias-pull-up;
			};

			/omit-if-no-ref/ lpuart1_cts_pa8: lpuart1_cts_pa8 {
				pinmux = <STM32_PINMUX('A', 8, AF8)>;
				bias-pull-up;
			};

			/omit-if-no-ref/ lpuart1_cts_pa11: lpuart1_cts_pa11 {
				pinmux = <STM32_PINMUX('A', 11, AF3)>;
				bias-pull-up;
			};

			/omit-if-no-ref/ usart1_cts_pa11: usart1_cts_pa11 {
				pinmux = <STM32_PINMUX('A', 11, AF7)>;
				bias-pull-up;
			};

			/omit-if-no-ref/ lpuart1_cts_pa13: lpuart1_cts_pa13 {
				pinmux = <STM32_PINMUX('A', 13, AF8)>;
				bias-pull-up;
			};

			/omit-if-no-ref/ usart1_cts_pa15: usart1_cts_pa15 {
				pinmux = <STM32_PINMUX('A', 15, AF8)>;
				bias-pull-up;
			};

			/omit-if-no-ref/ lpuart1_cts_pb13: lpuart1_cts_pb13 {
				pinmux = <STM32_PINMUX('B', 13, AF8)>;
				bias-pull-up;
			};

			/omit-if-no-ref/ usart2_cts_pa0: usart2_cts_pa0 {
				pinmux = <STM32_PINMUX('A', 0, AF7)>;
				bias-pull-up;
			};

			/omit-if-no-ref/ usart2_cts_pa5: usart2_cts_pa5 {
				pinmux = <STM32_PINMUX('A', 5, AF11)>;
				bias-pull-up;
			};

			/omit-if-no-ref/ usart2_cts_pb6: usart2_cts_pb6 {
				pinmux = <STM32_PINMUX('B', 6, AF11)>;
				bias-pull-up;
			};

			/omit-if-no-ref/ usart3_cts_pa0: usart3_cts_pa0 {
				pinmux = <STM32_PINMUX('A', 0, AF9)>;
				bias-pull-up;
			};

			/omit-if-no-ref/ usart3_cts_pb13: usart3_cts_pb13 {
				pinmux = <STM32_PINMUX('B', 13, AF7)>;
				bias-pull-up;
			};

			/omit-if-no-ref/ usart3_cts_pb15: usart3_cts_pb15 {
				pinmux = <STM32_PINMUX('B', 15, AF7)>;
				bias-pull-up;
			};

			/* UART_DE / USART_DE / LPUART_DE */

			/omit-if-no-ref/ usart1_de_pa4: usart1_de_pa4 {
				pinmux = <STM32_PINMUX('A', 4, AF8)>;
				drive-push-pull;
			};

			/omit-if-no-ref/ lpuart1_de_pa5: lpuart1_de_pa5 {
				pinmux = <STM32_PINMUX('A', 5, AF8)>;
				drive-push-pull;
			};

			/omit-if-no-ref/ usart1_de_pa7: usart1_de_pa7 {
				pinmux = <STM32_PINMUX('A', 7, AF8)>;
				drive-push-pull;
			};

			/omit-if-no-ref/ lpuart1_de_pa12: lpuart1_de_pa12 {
				pinmux = <STM32_PINMUX('A', 12, AF3)>;
				drive-push-pull;
			};

			/omit-if-no-ref/ usart1_de_pa12: usart1_de_pa12 {
				pinmux = <STM32_PINMUX('A', 12, AF7)>;
				drive-push-pull;
			};

			/omit-if-no-ref/ lpuart1_de_pa14: lpuart1_de_pa14 {
				pinmux = <STM32_PINMUX('A', 14, AF8)>;
				drive-push-pull;
			};

			/omit-if-no-ref/ lpuart1_de_pb14: lpuart1_de_pb14 {
				pinmux = <STM32_PINMUX('B', 14, AF8)>;
				drive-push-pull;
			};

			/omit-if-no-ref/ usart2_de_pa1: usart2_de_pa1 {
				pinmux = <STM32_PINMUX('A', 1, AF7)>;
				drive-push-pull;
			};

			/omit-if-no-ref/ usart2_de_pa15: usart2_de_pa15 {
				pinmux = <STM32_PINMUX('A', 15, AF11)>;
				drive-push-pull;
			};

			/omit-if-no-ref/ usart2_de_pb15: usart2_de_pb15 {
				pinmux = <STM32_PINMUX('B', 15, AF11)>;
				drive-push-pull;
			};

			/omit-if-no-ref/ usart3_de_pa7: usart3_de_pa7 {
				pinmux = <STM32_PINMUX('A', 7, AF9)>;
				drive-push-pull;
			};

			/omit-if-no-ref/ usart3_de_pa11: usart3_de_pa11 {
				pinmux = <STM32_PINMUX('A', 11, AF13)>;
				drive-push-pull;
			};

			/omit-if-no-ref/ usart3_de_pb14: usart3_de_pb14 {
				pinmux = <STM32_PINMUX('B', 14, AF7)>;
				drive-push-pull;
			};

			/* UART_RTS / USART_RTS / LPUART_RTS */

			/omit-if-no-ref/ usart1_rts_pa4: usart1_rts_pa4 {
				pinmux = <STM32_PINMUX('A', 4, AF8)>;
				drive-push-pull;
			};

			/omit-if-no-ref/ lpuart1_rts_pa5: lpuart1_rts_pa5 {
				pinmux = <STM32_PINMUX('A', 5, AF8)>;
				drive-push-pull;
			};

			/omit-if-no-ref/ usart1_rts_pa7: usart1_rts_pa7 {
				pinmux = <STM32_PINMUX('A', 7, AF8)>;
				drive-push-pull;
			};

			/omit-if-no-ref/ lpuart1_rts_pa12: lpuart1_rts_pa12 {
				pinmux = <STM32_PINMUX('A', 12, AF3)>;
				drive-push-pull;
			};

			/omit-if-no-ref/ usart1_rts_pa12: usart1_rts_pa12 {
				pinmux = <STM32_PINMUX('A', 12, AF7)>;
				drive-push-pull;
			};

			/omit-if-no-ref/ lpuart1_rts_pa14: lpuart1_rts_pa14 {
				pinmux = <STM32_PINMUX('A', 14, AF8)>;
				drive-push-pull;
			};

			/omit-if-no-ref/ lpuart1_rts_pb14: lpuart1_rts_pb14 {
				pinmux = <STM32_PINMUX('B', 14, AF8)>;
				drive-push-pull;
			};

			/omit-if-no-ref/ usart2_rts_pa1: usart2_rts_pa1 {
				pinmux = <STM32_PINMUX('A', 1, AF7)>;
				drive-push-pull;
			};

			/omit-if-no-ref/ usart2_rts_pa15: usart2_rts_pa15 {
				pinmux = <STM32_PINMUX('A', 15, AF11)>;
				drive-push-pull;
			};

			/omit-if-no-ref/ usart2_rts_pb15: usart2_rts_pb15 {
				pinmux = <STM32_PINMUX('B', 15, AF11)>;
				drive-push-pull;
			};

			/omit-if-no-ref/ usart3_rts_pa7: usart3_rts_pa7 {
				pinmux = <STM32_PINMUX('A', 7, AF9)>;
				drive-push-pull;
			};

			/omit-if-no-ref/ usart3_rts_pa11: usart3_rts_pa11 {
				pinmux = <STM32_PINMUX('A', 11, AF13)>;
				drive-push-pull;
			};

			/omit-if-no-ref/ usart3_rts_pb14: usart3_rts_pb14 {
				pinmux = <STM32_PINMUX('B', 14, AF7)>;
				drive-push-pull;
			};

			/* UART_RX / USART_RX / LPUART_RX */

			/omit-if-no-ref/ usart1_rx_pa1: usart1_rx_pa1 {
				pinmux = <STM32_PINMUX('A', 1, AF8)>;
			};

			/omit-if-no-ref/ lpuart1_rx_pa2: lpuart1_rx_pa2 {
				pinmux = <STM32_PINMUX('A', 2, AF3)>;
			};

			/omit-if-no-ref/ lpuart1_rx_pa10: lpuart1_rx_pa10 {
				pinmux = <STM32_PINMUX('A', 10, AF3)>;
			};

			/omit-if-no-ref/ usart1_rx_pa10: usart1_rx_pa10 {
				pinmux = <STM32_PINMUX('A', 10, AF7)>;
			};

			/omit-if-no-ref/ usart1_rx_pa11: usart1_rx_pa11 {
				pinmux = <STM32_PINMUX('A', 11, AF8)>;
			};

			/omit-if-no-ref/ usart1_rx_pa13: usart1_rx_pa13 {
				pinmux = <STM32_PINMUX('A', 13, AF7)>;
			};

			/omit-if-no-ref/ lpuart1_rx_pb7: lpuart1_rx_pb7 {
				pinmux = <STM32_PINMUX('B', 7, AF8)>;
			};

			/omit-if-no-ref/ usart1_rx_pb7: usart1_rx_pb7 {
				pinmux = <STM32_PINMUX('B', 7, AF7)>;
			};

			/omit-if-no-ref/ lpuart1_rx_pb15: lpuart1_rx_pb15 {
				pinmux = <STM32_PINMUX('B', 15, AF8)>;
			};

			/omit-if-no-ref/ usart1_rx_pb15: usart1_rx_pb15 {
				pinmux = <STM32_PINMUX('B', 15, AF4)>;
			};

			/omit-if-no-ref/ usart2_rx_pa3: usart2_rx_pa3 {
				pinmux = <STM32_PINMUX('A', 3, AF7)>;
			};

			/omit-if-no-ref/ usart2_rx_pa11: usart2_rx_pa11 {
				pinmux = <STM32_PINMUX('A', 11, AF4)>;
			};

			/omit-if-no-ref/ usart2_rx_pa13: usart2_rx_pa13 {
				pinmux = <STM32_PINMUX('A', 13, AF9)>;
			};

			/omit-if-no-ref/ usart2_rx_pa15: usart2_rx_pa15 {
				pinmux = <STM32_PINMUX('A', 15, AF9)>;
			};

			/omit-if-no-ref/ usart2_rx_pb1: usart2_rx_pb1 {
				pinmux = <STM32_PINMUX('B', 1, AF9)>;
			};

			/omit-if-no-ref/ usart2_rx_pb5: usart2_rx_pb5 {
				pinmux = <STM32_PINMUX('B', 5, AF13)>;
			};

			/omit-if-no-ref/ usart2_rx_pb15: usart2_rx_pb15 {
				pinmux = <STM32_PINMUX('B', 15, AF13)>;
			};

			/omit-if-no-ref/ usart3_rx_pa3: usart3_rx_pa3 {
				pinmux = <STM32_PINMUX('A', 3, AF13)>;
			};

			/omit-if-no-ref/ usart3_rx_pa5: usart3_rx_pa5 {
				pinmux = <STM32_PINMUX('A', 5, AF13)>;
			};

			/omit-if-no-ref/ usart3_rx_pa12: usart3_rx_pa12 {
				pinmux = <STM32_PINMUX('A', 12, AF13)>;
			};

			/omit-if-no-ref/ usart3_rx_pa15: usart3_rx_pa15 {
				pinmux = <STM32_PINMUX('A', 15, AF13)>;
			};

			/omit-if-no-ref/ usart3_rx_pb8: usart3_rx_pb8 {
				pinmux = <STM32_PINMUX('B', 8, AF13)>;
			};

			/* UART_TX / USART_TX / LPUART_TX */

			/omit-if-no-ref/ usart1_tx_pa2: usart1_tx_pa2 {
				pinmux = <STM32_PINMUX('A', 2, AF8)>;
				bias-pull-up;
			};

			/omit-if-no-ref/ lpuart1_tx_pa3: lpuart1_tx_pa3 {
				pinmux = <STM32_PINMUX('A', 3, AF3)>;
				bias-pull-up;
			};

			/omit-if-no-ref/ lpuart1_tx_pa9: lpuart1_tx_pa9 {
				pinmux = <STM32_PINMUX('A', 9, AF3)>;
				bias-pull-up;
			};

			/omit-if-no-ref/ usart1_tx_pa9: usart1_tx_pa9 {
				pinmux = <STM32_PINMUX('A', 9, AF7)>;
				bias-pull-up;
			};

			/omit-if-no-ref/ usart1_tx_pa12: usart1_tx_pa12 {
				pinmux = <STM32_PINMUX('A', 12, AF8)>;
				bias-pull-up;
			};

			/omit-if-no-ref/ usart1_tx_pa14: usart1_tx_pa14 {
				pinmux = <STM32_PINMUX('A', 14, AF7)>;
				bias-pull-up;
			};

			/omit-if-no-ref/ lpuart1_tx_pb6: lpuart1_tx_pb6 {
				pinmux = <STM32_PINMUX('B', 6, AF8)>;
				bias-pull-up;
			};

			/omit-if-no-ref/ usart1_tx_pb6: usart1_tx_pb6 {
				pinmux = <STM32_PINMUX('B', 6, AF7)>;
				bias-pull-up;
			};

			/omit-if-no-ref/ usart1_tx_pb14: usart1_tx_pb14 {
				pinmux = <STM32_PINMUX('B', 14, AF4)>;
				bias-pull-up;
			};

			/omit-if-no-ref/ usart2_tx_pa2: usart2_tx_pa2 {
				pinmux = <STM32_PINMUX('A', 2, AF7)>;
				bias-pull-up;
			};

			/omit-if-no-ref/ usart2_tx_pa5: usart2_tx_pa5 {
				pinmux = <STM32_PINMUX('A', 5, AF9)>;
				bias-pull-up;
			};

			/omit-if-no-ref/ usart2_tx_pa8: usart2_tx_pa8 {
				pinmux = <STM32_PINMUX('A', 8, AF4)>;
				bias-pull-up;
			};

			/omit-if-no-ref/ usart2_tx_pa12: usart2_tx_pa12 {
				pinmux = <STM32_PINMUX('A', 12, AF4)>;
				bias-pull-up;
			};

			/omit-if-no-ref/ usart2_tx_pa14: usart2_tx_pa14 {
				pinmux = <STM32_PINMUX('A', 14, AF9)>;
				bias-pull-up;
			};

			/omit-if-no-ref/ usart2_tx_pb0: usart2_tx_pb0 {
				pinmux = <STM32_PINMUX('B', 0, AF9)>;
				bias-pull-up;
			};

			/omit-if-no-ref/ usart2_tx_pb4: usart2_tx_pb4 {
				pinmux = <STM32_PINMUX('B', 4, AF13)>;
				bias-pull-up;
			};

			/omit-if-no-ref/ usart3_tx_pa4: usart3_tx_pa4 {
				pinmux = <STM32_PINMUX('A', 4, AF13)>;
				bias-pull-up;
			};

			/omit-if-no-ref/ usart3_tx_pa8: usart3_tx_pa8 {
				pinmux = <STM32_PINMUX('A', 8, AF13)>;
				bias-pull-up;
			};

			/omit-if-no-ref/ usart3_tx_pb3: usart3_tx_pb3 {
				pinmux = <STM32_PINMUX('B', 3, AF13)>;
				bias-pull-up;
			};

			/omit-if-no-ref/ usart3_tx_pb7: usart3_tx_pb7 {
				pinmux = <STM32_PINMUX('B', 7, AF13)>;
				bias-pull-up;
			};

			/omit-if-no-ref/ usart3_tx_pb10: usart3_tx_pb10 {
				pinmux = <STM32_PINMUX('B', 10, AF7)>;
				bias-pull-up;
			};

			/* USB */

			/omit-if-no-ref/ usb_dm_pa11: usb_dm_pa11 {
				pinmux = <STM32_PINMUX('A', 11, AF10)>;
			};

			/omit-if-no-ref/ usb_dp_pa12: usb_dp_pa12 {
				pinmux = <STM32_PINMUX('A', 12, AF10)>;
			};

		};
	};
};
